# ATtiny20 register map
Vendor: Atmel; File version: 1.0
CPU: other r0p0, little endian, no MPU, no FPU, 4 interrupt priority bits
Registers are 8-bit, read-write, reset 0x0 unless marked. A register's access mark holds for its fields unless they carry their own. Offsets are from the block's base; lines under a group give offsets from that group; [hi:lo] are bit positions; {n}, {i} and the like mark numbered series; 'fields as' and 'values as' point back to an identical list; <NAME> marks a mode.

## Memory map
0x00800000 PORTA blocks up to offset 0x9 — I/O Port
0x00800004 PORTB size 0x5 — I/O Port
0x00800009 EXINT blocks up to offset 0x32 — External Interrupts
0x0080000D ADC size 0x6 — Analog-to-Digital Converter
0x00800013 AC size 0x2 — Analog Comparator
0x00800015 TC0 blocks up to offset 0x13 — Timer/Counter, 8-bit
0x0080001A TC1 size 0xE — Timer/Counter, 16-bit
0x00800028 TWI size 0x6 — Two Wire Serial Interface
0x0080002E SPI size 0x3 — Serial Peripheral Interface
0x00800031 WDT size 0x1 — Watchdog Timer
0x00800032 CPU blocks up to offset 0xE — CPU Registers

## Interrupts
0 RESET (CPU) — External Reset, Power-on Reset and Watchdog Reset
1 INT0 (CPU) — External Interrupt Request 0
2 PCINT0 (CPU) — Pin Change Interrupt Request 0
3 PCINT1 (CPU) — Pin Change Interrupt Request 1
4 WDT (CPU) — Watchdog Time-out
5 TIM1_CAPT (CPU) — Timer/Counter1 Input Capture
6 TIM1_COMPA (CPU) — Timer/Counter1 Compare Match A
7 TIM1_COMPB (CPU) — Timer/Counter1 Compare Match B
8 TIM1_OVF (CPU) — Timer/Counter1 Overflow
9 TIM0_COMPA (CPU) — Timer/Counter0 Compare Match A
10 TIM0_COMPB (CPU) — Timer/Counter0 Compare Match B
11 TIM0_OVF (CPU) — Timer/Counter0 Overflow
12 ANA_COMP (CPU) — Analog Comparator
13 ADC_ADC (CPU) — Conversion Complete
14 TWI_SLAVE (CPU) — Two-Wire Interface
15 SPI (CPU) — Serial Peripheral Interface
16 QTRIP (CPU) — Touch Sensing

## AC — Analog Comparator
Base 0x00800013
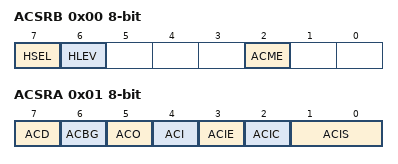
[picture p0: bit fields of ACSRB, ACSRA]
0x00 ACSRB — Analog Comparator Control And Status Register B
  [7] HSEL — Hysteresis Select
  [6] HLEV — Hysteresis Level
  [2] ACME — Analog Comparator Multiplexer Enable
0x01 ACSRA — Analog Comparator Control And Status Register A
  [7] ACD — Analog Comparator Disable
  [6] ACBG — Analog Comparator Bandgap Select
  [5] ACO — Analog Compare Output
  [4] ACI — Analog Comparator Interrupt Flag
  [3] ACIE — Analog Comparator Interrupt Enable
  [2] ACIC — Analog Comparator Input Capture Enable
  [1:0] ACIS — Analog Comparator Interrupt Mode Select bits
    0=INTERRUPT_ON_TOGGLE; 2=INTERRUPT_ON_FALLING_EDGE; 3=INTERRUPT_ON_RISING_EDGE

## ADC — Analog-to-Digital Converter
Base 0x0080000D
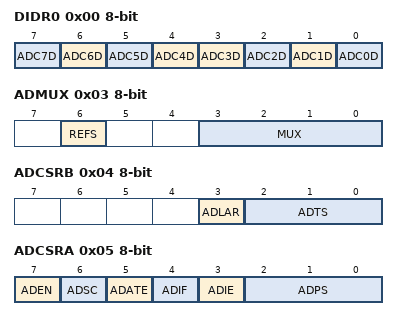
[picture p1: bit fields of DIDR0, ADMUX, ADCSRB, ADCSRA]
0x00 DIDR0 — Digital Input Disable Register 0
  [n] ADC{n}D (n=4..7) — ADC{n-1} Digital input Disable
  [3] ADC3D — AREF Digital Input Disable
  [2] ADC2D — ADC2 Digital input Disable
  [1] ADC1D — ADC1 Digital input Disable
  [0] ADC0D — ADC0 Digital input Disable
0x01 ADC 16-bit (reset mask 0xFF) — ADC Data Register Bytes
0x03 ADMUX — The ADC multiplexer Selection Register
  [6] REFS — Reference Selection Bit
    0=VCC_USED_AS_INTERNAL_REFERENCE; 1=INTERNAL_1_1V_REFERENCE
  [3:0] MUX — Analog Channel and Gain Selection Bits
    {v}=ADC{v} (v=0..7); 8=ADC_GND (0V (AGND)); 9=ADC_VBG (1.1V Internal Reference); 10=TEMPSENS (Temperature sensor)
0x04 ADCSRB — ADC Control and Status Register B
  [3] ADLAR
  [2:0] ADTS — ADC Auto Trigger Sources
    0=FREE_RUNNING_MODE; 1=ANALOG_COMPARATOR; 2=EXTERNAL_INTERRUPT_REQUEST_0; 3=TIMER_COUNTER0_COMPARE_MATCH_A; 4=TIMER_COUNTER0_OVERFLOW; 5=TIMER_COUNTER1_COMPARE_MATCH_B; 6=TIMER_COUNTER1_OVERFLOW; 7=WATCHDOG_INTERRUPT_REQUEST
0x05 ADCSRA — The ADC Control and Status register (read-only for debugger)
  [7] ADEN — ADC Enable
  [6] ADSC — ADC Start Conversion
  [5] ADATE — ADC Auto Trigger Enable
  [4] ADIF — ADC Interrupt Flag
  [3] ADIE — ADC Interrupt Enable
  [2:0] ADPS — ADC Prescaler Select Bits
    1=2; 2=4; 3=8; 4=16; 5=32; 6=64; 7=128

## CPU — CPU Registers
Base 0x00800032
0x00 NVMCSR — Non-Volatile Memory Control and Status Register
  [7] NVMBSY — Non-Volatile Memory Busy
0x01 NVMCMD — Non-Volatile Memory Command
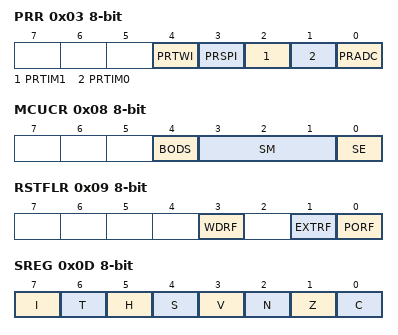
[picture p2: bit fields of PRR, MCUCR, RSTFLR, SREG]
0x03 PRR — Power Reduction Register
  [4] PRTWI — Power Reduction TWI
  [3] PRSPI — Power Reduction Serial Peripheral Interface
  [2] PRTIM1 — Power Reduction Timer/Counter1
  [1] PRTIM0 — Power Reduction Timer/Counter0
  [0] PRADC — Power Reduction ADC
0x04 CLKPSR — Clock Prescale Register
  [3:0] CLKPS — Clock Prescaler Select Bits
    0=1; 1=2; 2=4; 3=8; 4=16; 5=32; 6=64; 7=128; 8=256
0x05 CLKMSR — Clock Main Settings Register
  [1:0] CLKMS — Clock Main Select Bits
0x07 OSCCAL — Oscillator Calibration Value
  [7:0] OSCCAL — Oscillator Calibration
0x08 MCUCR — MCU Control Register
  [4] BODS — BOD Sleep
  [3:1] SM — Sleep Mode
    0=IDLE; 1=ADC (ADC noise reduction); 2=PDOWN (Power-down); 4=STDBY (Standby)
  [0] SE — Sleep Enable
0x09 RSTFLR — Reset Flag Register
  [3] WDRF — Watchdog Reset Flag
  [1] EXTRF — External Reset Flag
  [0] PORF — Power-on Reset Flag
0x0A CCP — Configuration Change Protection
0x0B SP 16-bit (reset mask 0xFF) — Stack Pointer
0x0D SREG — Status Register
  [7] I — Global Interrupt Enable
  [6] T — Bit Copy Storage
  [5] H — Half Carry Flag
  [4] S — Sign Bit
  [3] V — Two's Complement Overflow Flag
  [2] N — Negative Flag
  [1] Z — Zero Flag
  [0] C — Carry Flag
